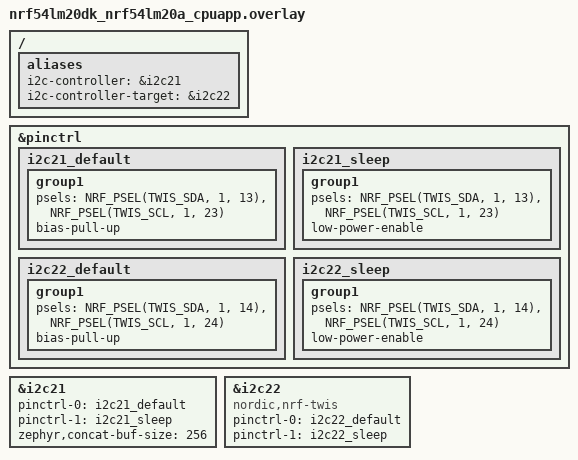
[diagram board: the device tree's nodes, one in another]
/*
 * Copyright (c) 2025 Nordic Semiconductor ASA
 *
 * SPDX-License-Identifier: Apache-2.0
 */

/*
 * SDA = P1.13 and P1.14
 * SCL = P1.23 and P1.24
 */

/ {
	aliases {
		i2c-controller = &i2c21;
		i2c-controller-target = &i2c22;
	};
};

&pinctrl {
	i2c21_default: i2c21_default {
		group1 {
			psels = <NRF_PSEL(TWIS_SDA, 1, 13)>,
				<NRF_PSEL(TWIS_SCL, 1, 23)>;
			bias-pull-up;
		};
	};

	i2c21_sleep: i2c21_sleep {
		group1 {
			psels = <NRF_PSEL(TWIS_SDA, 1, 13)>,
				<NRF_PSEL(TWIS_SCL, 1, 23)>;
			low-power-enable;
		};
	};

	i2c22_default: i2c22_default {
		group1 {
			psels = <NRF_PSEL(TWIS_SDA, 1, 14)>,
				<NRF_PSEL(TWIS_SCL, 1, 24)>;
			bias-pull-up;
		};
	};

	i2c22_sleep: i2c22_sleep {
		group1 {
			psels = <NRF_PSEL(TWIS_SDA, 1, 14)>,
				<NRF_PSEL(TWIS_SCL, 1, 24)>;
			low-power-enable;
		};
	};
};

&i2c21 {
	pinctrl-0 = <&i2c21_default>;
	pinctrl-1 = <&i2c21_sleep>;
	pinctrl-names = "default", "sleep";
	zephyr,concat-buf-size = <256>;
	status = "okay";
};

&i2c22 {
	compatible = "nordic,nrf-twis";
	pinctrl-0 = <&i2c22_default>;
	pinctrl-1 = <&i2c22_sleep>;
	pinctrl-names = "default", "sleep";
	status = "okay";
};
